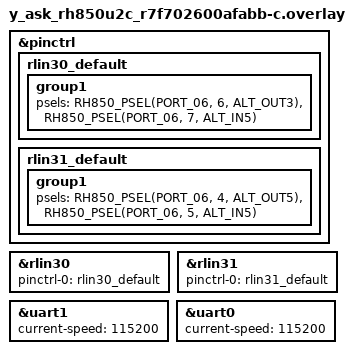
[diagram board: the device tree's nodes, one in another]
/*
 * Copyright (c) 2026 Renesas Electronics Corporation
 *
 * SPDX-License-Identifier: Apache-2.0
 */

&pinctrl {
	rlin30_default: rlin30_default {
		group1 {
			psels = <RH850_PSEL(PORT_06, 6, ALT_OUT3)>,
				<RH850_PSEL(PORT_06, 7, ALT_IN5)>;
		};
	};

	rlin31_default: rlin31_default {
		group1 {
			psels = <RH850_PSEL(PORT_06, 4, ALT_OUT5)>,
				<RH850_PSEL(PORT_06, 5, ALT_IN5)>;
		};
	};
};

&rlin30 {
	pinctrl-0 = <&rlin30_default>;
	pinctrl-names = "default";
	status = "okay";
};

&rlin31 {
	pinctrl-0 = <&rlin31_default>;
	pinctrl-names = "default";
	status = "okay";
};

dut: &uart1 {
	status = "okay";
	current-speed = <115200>;
};

dut_aux: &uart0 {
	status = "okay";
	current-speed = <115200>;
};
